# STM32F423xx register map
File version: 1.0
Registers are 32-bit, access not given, reset 0x0 unless marked. A register's access mark holds for its fields unless they carry their own. Offsets are from the block's base; [hi:lo] are bit positions; {n}, {i} and the like mark numbered series.

## SYSCFG
Base 0x40013800
0x00 MEMRMP
  [18] DFSDM2CKOSEL, [17] DFSDM2CFG, [16] ADC1DC2, [16] DFSDM2CK37SEL, [15] DFSDM2CK26SEL, [14] DFSDM2CK15SEL, [13] DFSDM2CK04SEL, [4n+3:4n] EXTI{n} (n=0..3), [4n-13:4n-16] EXTI{n} (n=4..7), [4n-29:4n-32] EXTI{n} (n=8..11), [4n-45:4n-48] EXTI{n} (n=12..15), [12] DFSDM2D6SEL, [11] DFSDM2D4SEL, [10] DFSDM2D2SEL, [9] DFSDM2D0SEL, [8] READY, [8] MCHDLY2EN, [7] DFSDM1CKOSEL, [6] DFSDM1CFG, [5] DFSDM1CK13SEL, [4] DFSDM1CK02SEL, [3] DFSDM1D2SEL, [2] PVD_LOCK, [2] DFSDM1D0SEL, [1] FMPI2C1_SDA, [1] MCHDLY1EN, [1:0] MEM_MODE, [0] LOCKUP_LOCK, [0] CMP_PD, [0] FMPI2C1_SCL, [0] BSCKSEL
0x04 PMC
0x08 EXTICR.0
0x0C EXTICR.1
0x10 EXTICR.2
0x14 EXTICR.3
0x1C CFGR2
0x20 CMPCR
0x2C CFGR
0x30 MCHDLYCR

## EXTI
Base 0x40013C00
0x00 IMR
  [23] MR23, [23] MR23, [23] TR23, [23] TR23, [n] SWIER{n} (n=0..23), [n] PR{n} (n=0..23), [22] MR22, [22] MR22, [22] TR22, [22] TR22, [21] MR21, [21] MR21, [21] TR21, [21] TR21, [20] MR20, [20] MR20, [20] TR20, [20] TR20, [19] MR19, [19] MR19, [19] TR19, [19] TR19, [18] MR18, [18] MR18, [18] TR18, [18] TR18, [17] MR17, [17] MR17, [17] TR17, [17] TR17, [16] MR16, [16] MR16, [16] TR16, [16] TR16, [15] MR15, [15] MR15, [15] TR15, [15] TR15, [14] MR14, [14] MR14, [14] TR14, [14] TR14, [13] MR13, [13] MR13, [13] TR13, [13] TR13, [12] MR12, [12] MR12, [12] TR12, [12] TR12, [11] MR11, [11] MR11, [11] TR11, [11] TR11, [10] MR10, [10] MR10, [10] TR10, [10] TR10, [9] MR9, [9] MR9, [9] TR9, [9] TR9, [8] MR8, [8] MR8, [8] TR8, [8] TR8, [7] MR7, [7] MR7, [7] TR7, [7] TR7, [6] MR6, [6] MR6, [6] TR6, [6] TR6, [5] MR5, [5] MR5, [5] TR5, [5] TR5, [4] MR4, [4] MR4, [4] TR4, [4] TR4, [3] MR3, [3] MR3, [3] TR3, [3] TR3, [2] MR2, [2] MR2, [2] TR2, [2] TR2, [1] MR1, [1] MR1, [1] TR1, [1] TR1, [0] MR0, [0] MR0, [0] TR0, [0] TR0
0x04 EMR
0x08 RTSR
0x0C FTSR
0x10 SWIER
0x14 PR

## SAI1
Base 0x40015800
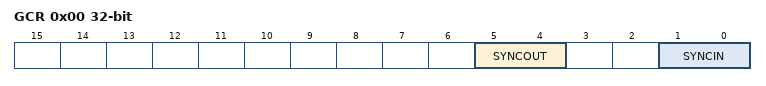
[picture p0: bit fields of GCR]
0x00 GCR
  [5:4] SYNCOUT, [1:0] SYNCIN
0x04 CR1A
0x08 CR2A
0x10 FRCRA
0x1C SLOTRA
0x24 CR1B
0x28 CR2B
0x2C IMRA
0x30 FRCRB
0x3C SLOTRB
0x40 SRA
0x4C IMRB
0x58 CLRFRA
0x60 SRB
0x74 DRA
0x78 CLRFRB
0x94 DRB

## GPIOA
Base 0x40020000
Same registers: GPIOB 0x40020400, GPIOC 0x40020800, GPIOD 0x40020C00, GPIOE 0x40021000, GPIOF 0x40021400, GPIOG 0x40021800, GPIOH 0x40021C00
0x00 MODER
  [n+16] BR{n} (n=0..15), [2n+1:2n] MODER{n} (n=0..15), [2n+1:2n] OSPEED{n} (n=0..15), [2n+1:2n] PUPD{n} (n=0..15), [4n-29:4n-32] AFSEL{n} (n=8..15), [n] OT{n} (n=0..15), [n] ID{n} (n=0..15), [n] OD{n} (n=0..15), [n] BS{n} (n=0..15)
0x04 OTYPER
0x08 OSPEEDR
0x0C PUPDR
0x10 IDR
0x14 ODR
0x18 BSRR
0x1C LCKR
0x20 AFR.0
0x24 AFR.1

## CRC
Base 0x40023000
0x00 DR
  [31:0] DR, [7:0] IDR, [0] RESET
0x04 IDR 8-bit
0x08 CR

## FLASH
Base 0x40023C00
0x00 ACR
  [31] LOCK, [25] ERRIE, [24] EOPIE, [16] BSY, [16] STRT, [30:16] nWRP, [27:16] nWRP, [12] DCRST, [11] ICRST, [10] DCEN, [9] ICEN, [8] PRFTEN, [8] RDERR, [9:8] PSIZE, [15:8] RDP, [7] PGSERR, [7] nRST_STDBY, [6] PGPERR, [6] nRST_STOP, [5] PGAERR, [5] WDG_SW, [4] WRPERR, [6:3] SNB, [2] MER, [3:2] BOR_LEV, [1] SOP, [1] SER, [1] OPTSTRT, [2:0] LATENCY, [0] EOP, [0] PG, [0] OPTLOCK
0x04 KEYR
0x08 OPTKEYR
0x0C SR
0x10 CR
0x14 OPTCR
0x18 OPTCR1

## DMA1
Base 0x40026000
Same registers: DMA2 0x40026400
0x00 LISR
  [27] TCIF3, [27] TCIF7, [27] CTCIF3, [27] CTCIF7, [26] HTIF3, [26] HTIF7, [26] CHTIF3, [26] CHTIF7, [25] TEIF3, [25] TEIF7, [25] CTEIF3, [25] CTEIF7, [24] DMEIF3, [24] DMEIF7, [24] CDMEIF3, [24] CDMEIF7, [22] FEIF3, [22] FEIF7, [22] CFEIF3, [22] CFEIF7, [21] TCIF2, [21] TCIF6, [21] CTCIF2, [21] CTCIF6, [20] HTIF2, [20] HTIF6, [20] CHTIF2, [20] CHTIF6, [19] TEIF2, [19] TEIF6, [19] CTEIF2, [19] CTEIF6, [18] DMEIF2, [18] DMEIF6, [18] CDMEIF2, [18] CDMEIF6, [16] FEIF2, [16] FEIF6, [16] CFEIF2, [16] CFEIF6, [11] TCIF1, [11] TCIF5, [11] CTCIF1, [11] CTCIF5, [10] HTIF1, [10] HTIF5, [10] CHTIF1, [10] CHTIF5, [9] TEIF1, [9] TEIF5, [9] CTEIF1, [9] CTEIF5, [8] DMEIF1, [8] DMEIF5, [8] CDMEIF1, [8] CDMEIF5, [6] FEIF1, [6] FEIF5, [6] CFEIF1, [6] CFEIF5, [5] TCIF0, [5] TCIF4, [5] CTCIF0, [5] CTCIF4, [4] HTIF0, [4] HTIF4, [4] CHTIF0, [4] CHTIF4, [3] TEIF0, [3] TEIF4, [3] CTEIF0, [3] CTEIF4, [2] DMEIF0, [2] DMEIF4, [2] CDMEIF0, [2] CDMEIF4, [0] FEIF0, [0] FEIF4, [0] CFEIF0, [0] CFEIF4
0x04 HISR
0x08 LIFCR
0x0C HIFCR
{0x10+0x18*i} CR{i} (i=0..7)
{0x14+0x18*i} NDTR{i} (i=0..7)
{0x1C+0x18*i} PAR{i} (i=0..7)
{0x28+0x18*i} M0AR{i} (i=0..7)
{0x38+0x18*i} M1AR{i} (i=0..7)
{0x4C+0x18*i} FCR{i} (i=0..7)
